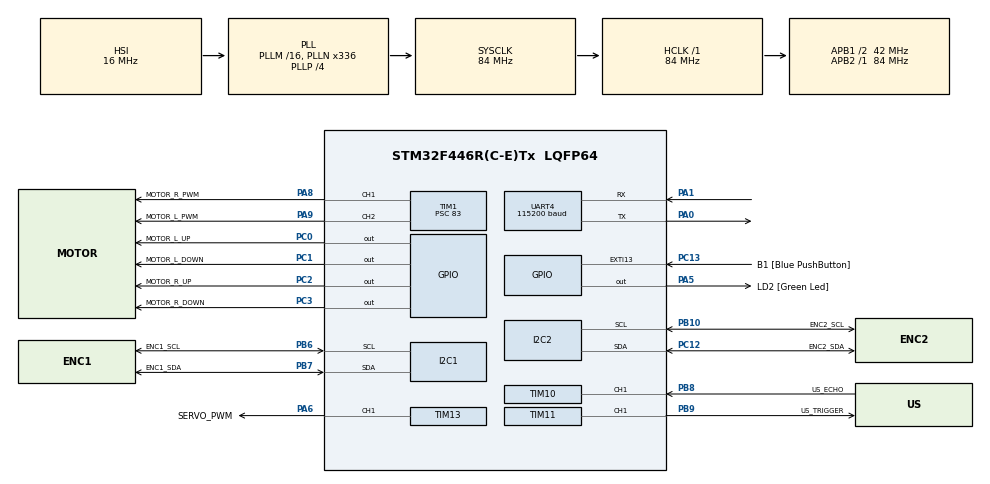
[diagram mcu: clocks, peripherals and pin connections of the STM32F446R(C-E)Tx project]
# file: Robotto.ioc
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Dma.Request0=UART4_RX
Dma.Request1=UART4_TX
Dma.UART4_RX.0.Direction=DMA_PERIPH_TO_MEMORY
Dma.UART4_RX.0.FIFOMode=DMA_FIFOMODE_DISABLE
Dma.UART4_RX.0.Instance=DMA1_Stream2
Dma.UART4_RX.0.MemDataAlignment=DMA_MDATAALIGN_BYTE
Dma.UART4_RX.0.MemInc=DMA_MINC_ENABLE
Dma.UART4_RX.0.Mode=DMA_CIRCULAR
Dma.UART4_RX.0.PeriphDataAlignment=DMA_PDATAALIGN_BYTE
Dma.UART4_RX.0.PeriphInc=DMA_PINC_DISABLE
Dma.UART4_RX.0.Priority=DMA_PRIORITY_LOW
Dma.UART4_TX.1.Direction=DMA_MEMORY_TO_PERIPH
Dma.UART4_TX.1.FIFOMode=DMA_FIFOMODE_DISABLE
Dma.UART4_TX.1.Instance=DMA1_Stream4
Dma.UART4_TX.1.MemDataAlignment=DMA_MDATAALIGN_BYTE
Dma.UART4_TX.1.MemInc=DMA_MINC_ENABLE
Dma.UART4_TX.1.Mode=DMA_NORMAL
Dma.UART4_TX.1.PeriphDataAlignment=DMA_PDATAALIGN_BYTE
Dma.UART4_TX.1.PeriphInc=DMA_PINC_DISABLE
Dma.UART4_TX.1.Priority=DMA_PRIORITY_LOW
Mcu.Family=STM32F4
Mcu.Name=STM32F446R(C-E)Tx
Mcu.Package=LQFP64
NVIC.DMA1_Stream2_IRQn=true\:6\:0\:true\:false\:true\:false\:true\:true
NVIC.DMA1_Stream4_IRQn=true\:6\:0\:true\:false\:true\:false\:true\:true
NVIC.EXTI15_10_IRQn=true\:15\:0\:true\:false\:true\:true\:true\:true
NVIC.PriorityGroup=NVIC_PRIORITYGROUP_4
NVIC.TIM1_UP_TIM10_IRQn=true\:5\:0\:true\:false\:true\:true\:true\:true
NVIC.TIM7_IRQn=true\:0\:0\:false\:false\:true\:false\:true\:true
NVIC.TimeBase=TIM7_IRQn
NVIC.TimeBaseIP=TIM7
NVIC.UART4_IRQn=true\:7\:0\:true\:false\:false\:true\:false\:true
PA0-WKUP.Mode=Asynchronous
PA0-WKUP.Signal=UART4_TX
PA1.Mode=Asynchronous
PA1.Signal=UART4_RX
PA13.GPIO_Label=TMS
PA13.Mode=Serial_Wire
PA13.Signal=SYS_JTMS-SWDIO
PA14.GPIO_Label=TCK
PA14.Mode=Serial_Wire
PA14.Signal=SYS_JTCK-SWCLK
PA5.GPIO_Label=LD2 [Green Led]
PA5.Signal=GPIO_Output
PA6.GPIO_Label=SERVO_PWM
PA6.Signal=S_TIM13_CH1
PA8.GPIO_Label=MOTOR_R_PWM
PA8.Signal=S_TIM1_CH1
PA9.GPIO_Label=MOTOR_L_PWM
PA9.Signal=S_TIM1_CH2
PB10.GPIO_Label=ENC2_SCL
PB10.Mode=I2C
PB10.Signal=I2C2_SCL
PB3.GPIO_Label=SWO
PB3.Signal=SYS_JTDO-SWO
PB6.GPIO_Label=ENC1_SCL
PB6.Mode=I2C
PB6.Signal=I2C1_SCL
PB7.GPIO_Label=ENC1_SDA
PB7.Mode=I2C
PB7.Signal=I2C1_SDA
PB8.GPIO_Label=US_ECHO
PB8.GPIO_ModeDefaultPP=GPIO_MODE_AF_PP
PB8.GPIO_PuPd=GPIO_NOPULL
PB8.GPIO_Speed=GPIO_SPEED_FREQ_LOW
PB8.Signal=S_TIM10_CH1
PB9.GPIO_Label=US_TRIGGER
PB9.GPIO_Speed=GPIO_SPEED_FREQ_HIGH
PB9.Signal=S_TIM11_CH1
PC0.GPIO_Label=MOTOR_L_UP
PC0.Signal=GPIO_Output
PC1.GPIO_Label=MOTOR_L_DOWN
PC1.Signal=GPIO_Output
PC12.GPIO_Label=ENC2_SDA
PC12.Mode=I2C
PC12.Signal=I2C2_SDA
PC13.GPIO_Label=B1 [Blue PushButton]
PC13.GPIO_ModeDefaultEXTI=GPIO_MODE_IT_FALLING
PC13.Signal=GPXTI13
PC2.GPIO_Label=MOTOR_R_UP
PC2.Signal=GPIO_Output
PC3.GPIO_Label=MOTOR_R_DOWN
PC3.Signal=GPIO_Output
ProjectManager.HeapSize=0x200
ProjectManager.StackSize=0x400
ProjectManager.TargetToolchain=STM32CubeIDE
RCC.AHBFreq_Value=84000000
RCC.APB1CLKDivider=RCC_HCLK_DIV2
RCC.APB1Freq_Value=42000000
RCC.APB1TimFreq_Value=84000000
RCC.APB2Freq_Value=84000000
RCC.APB2TimFreq_Value=84000000
RCC.CortexFreq_Value=84000000
RCC.HCLKFreq_Value=84000000
RCC.PLLN=336
RCC.PLLP=RCC_PLLP_DIV4
RCC.SYSCLKFreq_VALUE=84000000
RCC.SYSCLKSource=RCC_SYSCLKSOURCE_PLLCLK
RCC.USBFreq_Value=168000000
RCC.VCOOutputFreq_Value=336000000
SH.S_TIM10_CH1.0=TIM10_CH1,Input_Capture1_from_TI1
SH.S_TIM11_CH1.0=TIM11_CH1,PWM Generation1 CH1
SH.S_TIM13_CH1.0=TIM13_CH1,PWM Generation1 CH1
SH.S_TIM1_CH1.0=TIM1_CH1,PWM Generation1 CH1
SH.S_TIM1_CH2.0=TIM1_CH2,PWM Generation2 CH2
TIM1.Channel-PWM\ Generation1\ CH1=TIM_CHANNEL_1
TIM1.Channel-PWM\ Generation2\ CH2=TIM_CHANNEL_2
TIM1.Period=499
TIM1.Prescaler=83
TIM10.Channel=TIM_CHANNEL_1
TIM10.Prescaler=83
TIM11.Channel=TIM_CHANNEL_1
TIM11.OC1Preload_PWM=DISABLE
TIM11.Period=99
TIM11.Prescaler=83
TIM11.Pulse=99
TIM13.Channel=TIM_CHANNEL_1
TIM13.Period=20000
TIM13.Prescaler=83
TIM13.Pulse=1000
UART4.BaudRate=115200
UART4.VirtualMode=Asynchronous
VP_SYS_VS_tim7.Mode=TIM7
VP_TIM10_VS_ClockSourceINT.Mode=Enable_Timer
VP_TIM11_VS_ClockSourceINT.Mode=Enable_Timer
VP_TIM11_VS_OPM.Mode=OPM_bit
VP_TIM13_VS_ClockSourceINT.Mode=Enable_Timer
VP_TIM1_VS_ClockSourceINT.Mode=Internal
board=NUCLEO-F446RE

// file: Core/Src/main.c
/* USER CODE BEGIN Header */
/**
 ******************************************************************************
 * @file           : main.c
 * @brief          : Main program body
 ******************************************************************************
 * @attention
 *
 * Copyright (c) 2025 STMicroelectronics.
 * All rights reserved.
 *
 * This software is licensed under terms that can be found in the LICENSE file
 * in the root directory of this software component.
 * If no LICENSE file comes with this software, it is provided AS-IS.
 *
 ******************************************************************************
 */
/* USER CODE END Header */
#include "main.h"

/* USER CODE BEGIN Includes */
#include "SEGGER_RTT.h"
#include "FreeRTOS.h"
#include "task.h"
#include "SEGGER_SYSVIEW.h"
#include "SEGGER_SYSVIEW_FreeRTOS.h"

#include "robotto_setup.h"

/* USER CODE END Includes */

I2C_HandleTypeDef hi2c1;
I2C_HandleTypeDef hi2c2;

TIM_HandleTypeDef htim1;
TIM_HandleTypeDef htim10;
TIM_HandleTypeDef htim11;
TIM_HandleTypeDef htim13;

UART_HandleTypeDef huart4;
DMA_HandleTypeDef hdma_uart4_rx;
DMA_HandleTypeDef hdma_uart4_tx;

void SystemClock_Config(void);
static void MX_GPIO_Init(void);
static void MX_DMA_Init(void);
static void MX_TIM1_Init(void);
static void MX_I2C1_Init(void);
static void MX_I2C2_Init(void);
static void MX_UART4_Init(void);
static void MX_TIM10_Init(void);
static void MX_TIM11_Init(void);
static void MX_TIM13_Init(void);

int main(void)
{

  /* MCU Configuration--------------------------------------------------------*/

  /* Reset of all peripherals, Initializes the Flash interface and the Systick. */
  HAL_Init();

  /* Configure the system clock */
  SystemClock_Config();

  /* USER CODE BEGIN SysInit */
  traceSTART();
  /* USER CODE END SysInit */

  /* Initialize all configured peripherals */
  MX_GPIO_Init();
  MX_DMA_Init();
  MX_TIM1_Init();
  MX_I2C1_Init();
  MX_I2C2_Init();
  MX_UART4_Init();
  MX_TIM10_Init();
  MX_TIM11_Init();
  MX_TIM13_Init();
  /* USER CODE BEGIN 2 */

	if (Robotto_setup() != ROBOTTO_OK)
	{
		Error_Handler();
	}

	vTaskStartScheduler();

  /* USER CODE END 2 */

  /* Infinite loop */
	while (1)
	{

	}
}

void SystemClock_Config(void)
{
  RCC_OscInitTypeDef RCC_OscInitStruct = {0};
  RCC_ClkInitTypeDef RCC_ClkInitStruct = {0};

  /** Configure the main internal regulator output voltage
  */
  __HAL_RCC_PWR_CLK_ENABLE();
  __HAL_PWR_VOLTAGESCALING_CONFIG(PWR_REGULATOR_VOLTAGE_SCALE3);

  /** Initializes the RCC Oscillators according to the specified parameters
  * in the RCC_OscInitTypeDef structure.
  */
  RCC_OscInitStruct.OscillatorType = RCC_OSCILLATORTYPE_HSI;
  RCC_OscInitStruct.HSIState = RCC_HSI_ON;
  RCC_OscInitStruct.HSICalibrationValue = RCC_HSICALIBRATION_DEFAULT;
  RCC_OscInitStruct.PLL.PLLState = RCC_PLL_ON;
  RCC_OscInitStruct.PLL.PLLSource = RCC_PLLSOURCE_HSI;
  RCC_OscInitStruct.PLL.PLLM = 16;
  RCC_OscInitStruct.PLL.PLLN = 336;
  RCC_OscInitStruct.PLL.PLLP = RCC_PLLP_DIV4;
  RCC_OscInitStruct.PLL.PLLQ = 2;
  RCC_OscInitStruct.PLL.PLLR = 2;
  if (HAL_RCC_OscConfig(&RCC_OscInitStruct) != HAL_OK)
  {
    Error_Handler();
  }

  /** Initializes the CPU, AHB and APB buses clocks
  */
  RCC_ClkInitStruct.ClockType = RCC_CLOCKTYPE_HCLK|RCC_CLOCKTYPE_SYSCLK
                              |RCC_CLOCKTYPE_PCLK1|RCC_CLOCKTYPE_PCLK2;
  RCC_ClkInitStruct.SYSCLKSource = RCC_SYSCLKSOURCE_PLLCLK;
  RCC_ClkInitStruct.AHBCLKDivider = RCC_SYSCLK_DIV1;
  RCC_ClkInitStruct.APB1CLKDivider = RCC_HCLK_DIV2;
  RCC_ClkInitStruct.APB2CLKDivider = RCC_HCLK_DIV1;

  if (HAL_RCC_ClockConfig(&RCC_ClkInitStruct, FLASH_LATENCY_2) != HAL_OK)
  {
    Error_Handler();
  }
}

static void MX_I2C1_Init(void)
{

  hi2c1.Instance = I2C1;
  hi2c1.Init.ClockSpeed = 100000;
  hi2c1.Init.DutyCycle = I2C_DUTYCYCLE_2;
  hi2c1.Init.OwnAddress1 = 0;
  hi2c1.Init.AddressingMode = I2C_ADDRESSINGMODE_7BIT;
  hi2c1.Init.DualAddressMode = I2C_DUALADDRESS_DISABLE;
  hi2c1.Init.OwnAddress2 = 0;
  hi2c1.Init.GeneralCallMode = I2C_GENERALCALL_DISABLE;
  hi2c1.Init.NoStretchMode = I2C_NOSTRETCH_DISABLE;
  if (HAL_I2C_Init(&hi2c1) != HAL_OK)
  {
    Error_Handler();
  }

}

static void MX_I2C2_Init(void)
{

  hi2c2.Instance = I2C2;
  hi2c2.Init.ClockSpeed = 100000;
  hi2c2.Init.DutyCycle = I2C_DUTYCYCLE_2;
  hi2c2.Init.OwnAddress1 = 0;
  hi2c2.Init.AddressingMode = I2C_ADDRESSINGMODE_7BIT;
  hi2c2.Init.DualAddressMode = I2C_DUALADDRESS_DISABLE;
  hi2c2.Init.OwnAddress2 = 0;
  hi2c2.Init.GeneralCallMode = I2C_GENERALCALL_DISABLE;
  hi2c2.Init.NoStretchMode = I2C_NOSTRETCH_DISABLE;
  if (HAL_I2C_Init(&hi2c2) != HAL_OK)
  {
    Error_Handler();
  }

}

static void MX_TIM1_Init(void)
{

  TIM_ClockConfigTypeDef sClockSourceConfig = {0};
  TIM_MasterConfigTypeDef sMasterConfig = {0};
  TIM_OC_InitTypeDef sConfigOC = {0};
  TIM_BreakDeadTimeConfigTypeDef sBreakDeadTimeConfig = {0};

  htim1.Instance = TIM1;
  htim1.Init.Prescaler = 83;
  htim1.Init.CounterMode = TIM_COUNTERMODE_UP;
  htim1.Init.Period = 499;
  htim1.Init.ClockDivision = TIM_CLOCKDIVISION_DIV1;
  htim1.Init.RepetitionCounter = 0;
  htim1.Init.AutoReloadPreload = TIM_AUTORELOAD_PRELOAD_DISABLE;
  if (HAL_TIM_Base_Init(&htim1) != HAL_OK)
  {
    Error_Handler();
  }
  sClockSourceConfig.ClockSource = TIM_CLOCKSOURCE_INTERNAL;
  if (HAL_TIM_ConfigClockSource(&htim1, &sClockSourceConfig) != HAL_OK)
  {
    Error_Handler();
  }
  if (HAL_TIM_PWM_Init(&htim1) != HAL_OK)
  {
    Error_Handler();
  }
  sMasterConfig.MasterOutputTrigger = TIM_TRGO_RESET;
  sMasterConfig.MasterSlaveMode = TIM_MASTERSLAVEMODE_DISABLE;
  if (HAL_TIMEx_MasterConfigSynchronization(&htim1, &sMasterConfig) != HAL_OK)
  {
    Error_Handler();
  }
  sConfigOC.OCMode = TIM_OCMODE_PWM1;
  sConfigOC.Pulse = 0;
  sConfigOC.OCPolarity = TIM_OCPOLARITY_HIGH;
  sConfigOC.OCNPolarity = TIM_OCNPOLARITY_HIGH;
  sConfigOC.OCFastMode = TIM_OCFAST_DISABLE;
  sConfigOC.OCIdleState = TIM_OCIDLESTATE_RESET;
  sConfigOC.OCNIdleState = TIM_OCNIDLESTATE_RESET;
  if (HAL_TIM_PWM_ConfigChannel(&htim1, &sConfigOC, TIM_CHANNEL_1) != HAL_OK)
  {
    Error_Handler();
  }
  if (HAL_TIM_PWM_ConfigChannel(&htim1, &sConfigOC, TIM_CHANNEL_2) != HAL_OK)
  {
    Error_Handler();
  }
  sBreakDeadTimeConfig.OffStateRunMode = TIM_OSSR_DISABLE;
  sBreakDeadTimeConfig.OffStateIDLEMode = TIM_OSSI_DISABLE;
  sBreakDeadTimeConfig.LockLevel = TIM_LOCKLEVEL_OFF;
  sBreakDeadTimeConfig.DeadTime = 0;
  sBreakDeadTimeConfig.BreakState = TIM_BREAK_DISABLE;
  sBreakDeadTimeConfig.BreakPolarity = TIM_BREAKPOLARITY_HIGH;
  sBreakDeadTimeConfig.AutomaticOutput = TIM_AUTOMATICOUTPUT_DISABLE;
  if (HAL_TIMEx_ConfigBreakDeadTime(&htim1, &sBreakDeadTimeConfig) != HAL_OK)
  {
    Error_Handler();
  }
  HAL_TIM_MspPostInit(&htim1);

}

static void MX_TIM10_Init(void)
{

  TIM_IC_InitTypeDef sConfigIC = {0};

  htim10.Instance = TIM10;
  htim10.Init.Prescaler = 83;
  htim10.Init.CounterMode = TIM_COUNTERMODE_UP;
  htim10.Init.Period = 65535;
  htim10.Init.ClockDivision = TIM_CLOCKDIVISION_DIV1;
  htim10.Init.AutoReloadPreload = TIM_AUTORELOAD_PRELOAD_DISABLE;
  if (HAL_TIM_Base_Init(&htim10) != HAL_OK)
  {
    Error_Handler();
  }
  if (HAL_TIM_IC_Init(&htim10) != HAL_OK)
  {
    Error_Handler();
  }
  sConfigIC.ICPolarity = TIM_INPUTCHANNELPOLARITY_RISING;
  sConfigIC.ICSelection = TIM_ICSELECTION_DIRECTTI;
  sConfigIC.ICPrescaler = TIM_ICPSC_DIV1;
  sConfigIC.ICFilter = 0;
  if (HAL_TIM_IC_ConfigChannel(&htim10, &sConfigIC, TIM_CHANNEL_1) != HAL_OK)
  {
    Error_Handler();
  }

}

static void MX_TIM11_Init(void)
{

  TIM_OC_InitTypeDef sConfigOC = {0};

  htim11.Instance = TIM11;
  htim11.Init.Prescaler = 83;
  htim11.Init.CounterMode = TIM_COUNTERMODE_UP;
  htim11.Init.Period = 99;
  htim11.Init.ClockDivision = TIM_CLOCKDIVISION_DIV1;
  htim11.Init.AutoReloadPreload = TIM_AUTORELOAD_PRELOAD_DISABLE;
  if (HAL_TIM_Base_Init(&htim11) != HAL_OK)
  {
    Error_Handler();
  }
  if (HAL_TIM_PWM_Init(&htim11) != HAL_OK)
  {
    Error_Handler();
  }
  if (HAL_TIM_OnePulse_Init(&htim11, TIM_OPMODE_SINGLE) != HAL_OK)
  {
    Error_Handler();
  }
  sConfigOC.OCMode = TIM_OCMODE_PWM1;
  sConfigOC.Pulse = 99;
  sConfigOC.OCPolarity = TIM_OCPOLARITY_HIGH;
  sConfigOC.OCFastMode = TIM_OCFAST_DISABLE;
  if (HAL_TIM_PWM_ConfigChannel(&htim11, &sConfigOC, TIM_CHANNEL_1) != HAL_OK)
  {
    Error_Handler();
  }
  __HAL_TIM_DISABLE_OCxPRELOAD(&htim11, TIM_CHANNEL_1);
  HAL_TIM_MspPostInit(&htim11);

}

static void MX_TIM13_Init(void)
{

  TIM_OC_InitTypeDef sConfigOC = {0};

  htim13.Instance = TIM13;
  htim13.Init.Prescaler = 83;
  htim13.Init.CounterMode = TIM_COUNTERMODE_UP;
  htim13.Init.Period = 20000;
  htim13.Init.ClockDivision = TIM_CLOCKDIVISION_DIV1;
  htim13.Init.AutoReloadPreload = TIM_AUTORELOAD_PRELOAD_DISABLE;
  if (HAL_TIM_Base_Init(&htim13) != HAL_OK)
  {
    Error_Handler();
  }
  if (HAL_TIM_PWM_Init(&htim13) != HAL_OK)
  {
    Error_Handler();
  }
  sConfigOC.OCMode = TIM_OCMODE_PWM1;
  sConfigOC.Pulse = 1000;
  sConfigOC.OCPolarity = TIM_OCPOLARITY_HIGH;
  sConfigOC.OCFastMode = TIM_OCFAST_DISABLE;
  if (HAL_TIM_PWM_ConfigChannel(&htim13, &sConfigOC, TIM_CHANNEL_1) != HAL_OK)
  {
    Error_Handler();
  }
  HAL_TIM_MspPostInit(&htim13);

}

static void MX_UART4_Init(void)
{

  huart4.Instance = UART4;
  huart4.Init.BaudRate = 115200;
  huart4.Init.WordLength = UART_WORDLENGTH_8B;
  huart4.Init.StopBits = UART_STOPBITS_1;
  huart4.Init.Parity = UART_PARITY_NONE;
  huart4.Init.Mode = UART_MODE_TX_RX;
  huart4.Init.HwFlowCtl = UART_HWCONTROL_NONE;
  huart4.Init.OverSampling = UART_OVERSAMPLING_16;
  if (HAL_UART_Init(&huart4) != HAL_OK)
  {
    Error_Handler();
  }

}

static void MX_DMA_Init(void)
{

  /* DMA controller clock enable */
  __HAL_RCC_DMA1_CLK_ENABLE();

  /* DMA interrupt init */
  /* DMA1_Stream2_IRQn interrupt configuration */
  HAL_NVIC_SetPriority(DMA1_Stream2_IRQn, 6, 0);
  HAL_NVIC_EnableIRQ(DMA1_Stream2_IRQn);
  /* DMA1_Stream4_IRQn interrupt configuration */
  HAL_NVIC_SetPriority(DMA1_Stream4_IRQn, 6, 0);
  HAL_NVIC_EnableIRQ(DMA1_Stream4_IRQn);

}

static void MX_GPIO_Init(void)
{
  GPIO_InitTypeDef GPIO_InitStruct = {0};

  /* GPIO Ports Clock Enable */
  __HAL_RCC_GPIOC_CLK_ENABLE();
  __HAL_RCC_GPIOA_CLK_ENABLE();
  __HAL_RCC_GPIOB_CLK_ENABLE();

  /*Configure GPIO pin Output Level */
  HAL_GPIO_WritePin(GPIOC, MOTOR_L_UP_Pin|MOTOR_L_DOWN_Pin|MOTOR_R_UP_Pin|MOTOR_R_DOWN_Pin, GPIO_PIN_RESET);

  /*Configure GPIO pin Output Level */
  HAL_GPIO_WritePin(LD2_GPIO_Port, LD2_Pin, GPIO_PIN_RESET);

  /*Configure GPIO pin : B1_Pin */
  GPIO_InitStruct.Pin = B1_Pin;
  GPIO_InitStruct.Mode = GPIO_MODE_IT_FALLING;
  GPIO_InitStruct.Pull = GPIO_NOPULL;
  HAL_GPIO_Init(B1_GPIO_Port, &GPIO_InitStruct);

  /*Configure GPIO pins : MOTOR_L_UP_Pin MOTOR_L_DOWN_Pin MOTOR_R_UP_Pin MOTOR_R_DOWN_Pin */
  GPIO_InitStruct.Pin = MOTOR_L_UP_Pin|MOTOR_L_DOWN_Pin|MOTOR_R_UP_Pin|MOTOR_R_DOWN_Pin;
  GPIO_InitStruct.Mode = GPIO_MODE_OUTPUT_PP;
  GPIO_InitStruct.Pull = GPIO_NOPULL;
  GPIO_InitStruct.Speed = GPIO_SPEED_FREQ_LOW;
  HAL_GPIO_Init(GPIOC, &GPIO_InitStruct);

  /*Configure GPIO pin : LD2_Pin */
  GPIO_InitStruct.Pin = LD2_Pin;
  GPIO_InitStruct.Mode = GPIO_MODE_OUTPUT_PP;
  GPIO_InitStruct.Pull = GPIO_NOPULL;
  GPIO_InitStruct.Speed = GPIO_SPEED_FREQ_LOW;
  HAL_GPIO_Init(LD2_GPIO_Port, &GPIO_InitStruct);

  /* EXTI interrupt init*/
  HAL_NVIC_SetPriority(EXTI15_10_IRQn, 15, 0);
  HAL_NVIC_EnableIRQ(EXTI15_10_IRQn);

}

void HAL_TIM_PeriodElapsedCallback(TIM_HandleTypeDef *htim)
{
  if (htim->Instance == TIM7)
  {
    HAL_IncTick();
  }
}

void Error_Handler(void)
{
	__disable_irq();
	while (1)
	{
	}
}
